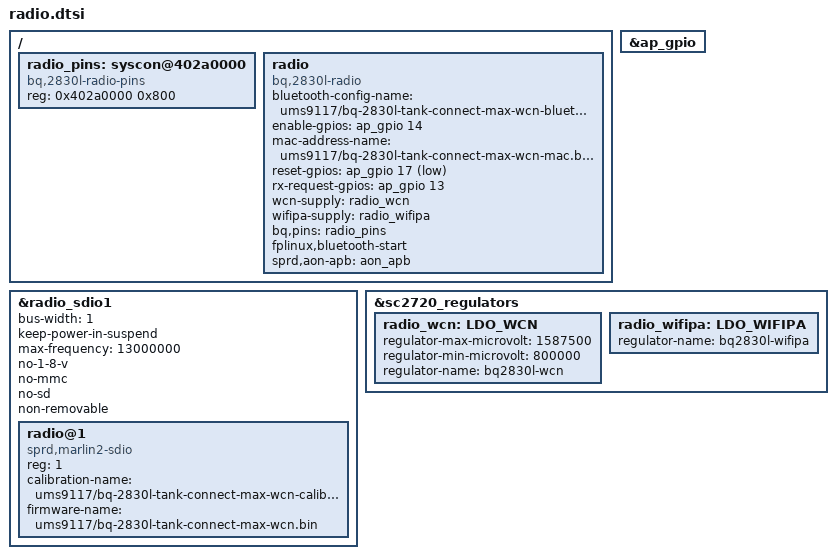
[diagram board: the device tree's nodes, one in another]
// SPDX-License-Identifier: GPL-2.0-only

#include <dt-bindings/gpio/gpio.h>
#include "ums9117-marlin2-sdio.dtsi"

/ {
	radio_pins: syscon@402a0000 {
		compatible = "bq,2830l-radio-pins", "syscon";
		reg = <0x402a0000 0x800>;
	};

	radio {
		compatible = "bq,2830l-radio";
		bluetooth-config-name = "ums9117/bq-2830l-tank-connect-max-wcn-bluetooth.bin";
		enable-gpios = <&ap_gpio 14 GPIO_ACTIVE_HIGH>;
		mac-address-name = "ums9117/bq-2830l-tank-connect-max-wcn-mac.bin";
		reset-gpios = <&ap_gpio 17 GPIO_ACTIVE_LOW>;
		rx-request-gpios = <&ap_gpio 13 GPIO_ACTIVE_HIGH>;
		wcn-supply = <&radio_wcn>;
		wifipa-supply = <&radio_wifipa>;
		bq,pins = <&radio_pins>;
		fplinux,bluetooth-start;
		sprd,aon-apb = <&aon_apb>;
	};
};

&radio_sdio1 {
	bus-width = <1>;
	keep-power-in-suspend;
	max-frequency = <13000000>;
	no-1-8-v;
	no-mmc;
	no-sd;
	non-removable;

	radio@1 {
		compatible = "sprd,marlin2-sdio";
		reg = <1>;
		calibration-name = "ums9117/bq-2830l-tank-connect-max-wcn-calibration.bin";
		firmware-name = "ums9117/bq-2830l-tank-connect-max-wcn.bin";
	};
};

&ap_gpio {
	status = "okay";
};

&sc2720_regulators {
	radio_wcn: LDO_WCN {
		regulator-max-microvolt = <1587500>;
		regulator-min-microvolt = <800000>;
		regulator-name = "bq2830l-wcn";
	};

	radio_wifipa: LDO_WIFIPA {
		regulator-name = "bq2830l-wifipa";
	};
};
